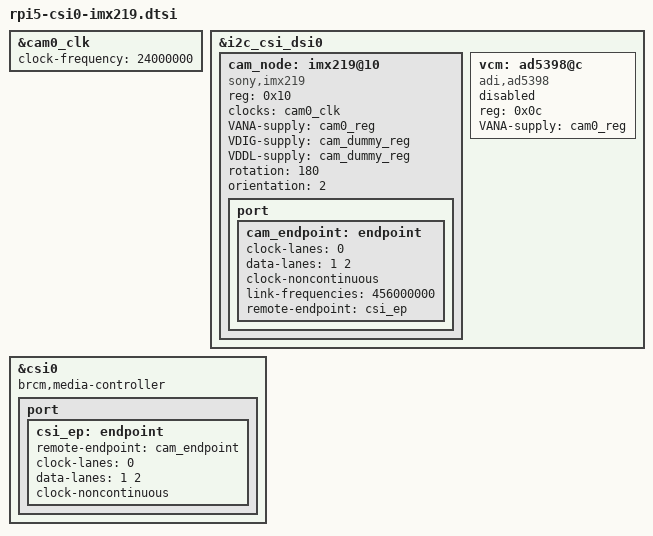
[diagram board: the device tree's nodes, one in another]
/* IMX219 Camera on CSI0 */

&cam0_clk {
	status = "okay";
	clock-frequency = <24000000>;
};

&i2c_csi_dsi0 {
	#address-cells = <1>;
	#size-cells = <0>;
	status = "okay";

	cam_node: imx219@10 {
		compatible = "sony,imx219";
		reg = <0x10>;
		status = "disabled";

		clocks = <&cam0_clk>;
		clock-names = "xclk";

		VANA-supply = <&cam0_reg>;	/* 2.8v */
		VDIG-supply = <&cam_dummy_reg>;	/* 1.8v */
		VDDL-supply = <&cam_dummy_reg>;	/* 1.2v */

		rotation = <180>;
		orientation = <2>;

		port {
			cam_endpoint: endpoint {
				clock-lanes = <0>;
				data-lanes = <1 2>;
				clock-noncontinuous;
				link-frequencies =
					/bits/ 64 <456000000>;
			};
		};
	};

	vcm: ad5398@c {
		compatible = "adi,ad5398";
		reg = <0x0c>;
		status = "disabled";
		VANA-supply = <&cam0_reg>;
	};
};

&csi0 {
	status = "okay";
	brcm,media-controller;

	port {
		csi_ep: endpoint {
			remote-endpoint = <&cam_endpoint>;
			clock-lanes = <0>;
			data-lanes = <1 2>;
			clock-noncontinuous;
		};
	};
};

&cam_node {
	status = "okay";
};

&cam_endpoint {
	remote-endpoint = <&csi_ep>;
};
